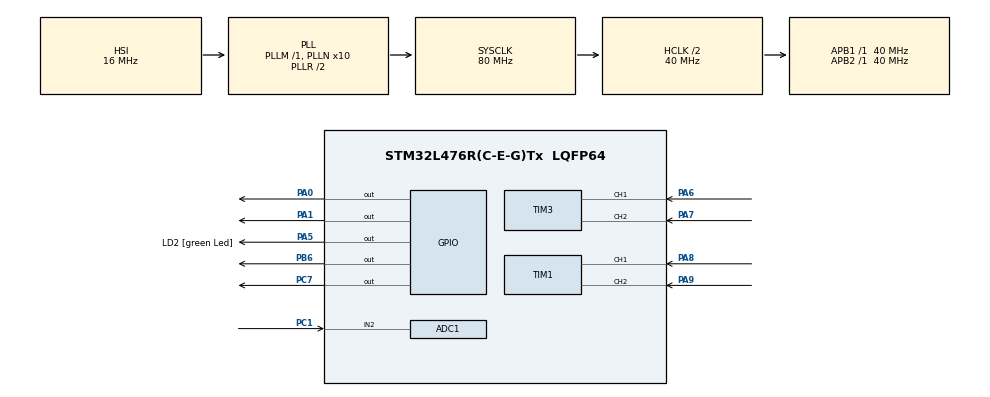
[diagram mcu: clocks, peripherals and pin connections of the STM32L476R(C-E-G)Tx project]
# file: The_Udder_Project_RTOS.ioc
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ADC1.Channel-0\#ChannelRegularConversion=ADC_CHANNEL_2
ADC1.ContinuousConvMode=ENABLE
ADC1.NbrOfConversionFlag=1
ADC1.OffsetNumber-0\#ChannelRegularConversion=ADC_OFFSET_NONE
ADC1.Rank-0\#ChannelRegularConversion=1
ADC1.SamplingTime-0\#ChannelRegularConversion=ADC_SAMPLETIME_2CYCLES_5
ADC1.master=1
Mcu.Family=STM32L4
Mcu.Name=STM32L476R(C-E-G)Tx
Mcu.Package=LQFP64
NVIC.PriorityGroup=NVIC_PRIORITYGROUP_4
PA0.GPIO_ModeDefaultOutputPP=GPIO_MODE_OUTPUT_PP
PA0.GPIO_PuPd=GPIO_PULLDOWN
PA0.GPIO_Speed=GPIO_SPEED_FREQ_LOW
PA0.PinState=GPIO_PIN_RESET
PA0.Signal=GPIO_Output
PA1.GPIO_PuPd=GPIO_PULLDOWN
PA1.Signal=GPIO_Output
PA13\ (JTMS-SWDIO).Mode=Trace_Asynchronous_SW
PA13\ (JTMS-SWDIO).Signal=SYS_JTMS-SWDIO
PA14\ (JTCK-SWCLK).Mode=Trace_Asynchronous_SW
PA14\ (JTCK-SWCLK).Signal=SYS_JTCK-SWCLK
PA5.GPIO_Label=LD2 [green Led]
PA5.GPIO_ModeDefaultOutputPP=GPIO_MODE_OUTPUT_PP
PA5.GPIO_PuPd=GPIO_NOPULL
PA5.GPIO_Speed=GPIO_SPEED_FREQ_LOW
PA5.Signal=GPIO_Output
PA6.Signal=S_TIM3_CH1
PA7.Signal=S_TIM3_CH2
PA8.Signal=S_TIM1_CH1
PA9.Signal=S_TIM1_CH2
PB3\ (JTDO-TRACESWO).Mode=Trace_Asynchronous_SW
PB3\ (JTDO-TRACESWO).Signal=SYS_JTDO-SWO
PB6.GPIO_PuPd=GPIO_PULLDOWN
PB6.Signal=GPIO_Output
PC1.Signal=ADCx_IN2
PC7.GPIO_PuPd=GPIO_PULLDOWN
PC7.Signal=GPIO_Output
PH0-OSC_IN\ (PH0).Mode=HSE-External-Oscillator
PH0-OSC_IN\ (PH0).Signal=RCC_OSC_IN
PH1-OSC_OUT\ (PH1).Mode=HSE-External-Oscillator
PH1-OSC_OUT\ (PH1).Signal=RCC_OSC_OUT
ProjectManager.HeapSize=0x200
ProjectManager.StackSize=0x400
ProjectManager.TargetToolchain=MDK-ARM V5.32
RCC.ADCFreq_Value=64000000
RCC.AHBCLKDivider=RCC_SYSCLK_DIV2
RCC.AHBFreq_Value=40000000
RCC.APB1Freq_Value=40000000
RCC.APB1TimFreq_Value=40000000
RCC.APB2Freq_Value=40000000
RCC.APB2TimFreq_Value=40000000
RCC.CortexFreq_Value=40000000
RCC.HCLKFreq_Value=40000000
RCC.HSE_VALUE=8000000
RCC.HSI_VALUE=16000000
RCC.LSE_VALUE=32768
RCC.MSI_VALUE=4000000
RCC.PLLN=10
RCC.PLLSourceVirtual=RCC_PLLSOURCE_HSI
RCC.PREFETCH_ENABLE=1
RCC.SYSCLKFreq_VALUE=80000000
RCC.SYSCLKSource=RCC_SYSCLKSOURCE_PLLCLK
RCC.USBFreq_Value=64000000
RCC.VCOOutputFreq_Value=160000000
SH.ADCx_IN2.0=ADC1_IN2,IN2-Single-Ended
SH.S_TIM1_CH1.0=TIM1_CH1,Encoder_Interface
SH.S_TIM1_CH2.0=TIM1_CH2,Encoder_Interface
SH.S_TIM3_CH1.0=TIM3_CH1,Encoder_Interface
SH.S_TIM3_CH2.0=TIM3_CH2,Encoder_Interface
TIM1.EncoderMode=TIM_ENCODERMODE_TI12
TIM3.EncoderMode=TIM_ENCODERMODE_TI12
board=NUCLEO-L476RG

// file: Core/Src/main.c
/* USER CODE BEGIN Header */
/**
  ******************************************************************************
  * @file           : main.c
  * @brief          : Main program body
  ******************************************************************************
  * @attention
  *
  * Copyright (c) 2023 STMicroelectronics.
  * All rights reserved.
  *
  * This software is licensed under terms that can be found in the LICENSE file
  * in the root directory of this software component.
  * If no LICENSE file comes with this software, it is provided AS-IS.
  *
  ******************************************************************************
  */
/* USER CODE END Header */
#include "main.h"
#include "adc.h"
#include "tim.h"
#include "gpio.h"

/* USER CODE BEGIN Includes */
#include <stdio.h>
#include "application.h"
#include "controller.h"
#include "peripherals.h"
/* USER CODE END Includes */

void SystemClock_Config(void);

/* USER CODE BEGIN 0 */
uint32_t Main_GetTickMillisec(void) {return HAL_GetTick();}
/* USER CODE END 0 */

int main(void)
{

  /* MCU Configuration--------------------------------------------------------*/

  /* Reset of all peripherals, Initializes the Flash interface and the Systick. */
  HAL_Init();

  /* Configure the system clock */
  SystemClock_Config();

  /* Initialize all configured peripherals */
  MX_GPIO_Init();
  MX_ADC1_Init();
  MX_TIM1_Init();
  MX_TIM3_Init();
  /* USER CODE BEGIN 2 */
	Application_Setup();
  /* USER CODE END 2 */

  /* Infinite loop */
  /* USER CODE BEGIN WHILE */
  while (1)
  {
		Application_Loop();
    /* USER CODE END WHILE */

  }
}

void SystemClock_Config(void)
{
  RCC_OscInitTypeDef RCC_OscInitStruct = {0};
  RCC_ClkInitTypeDef RCC_ClkInitStruct = {0};

  /** Configure the main internal regulator output voltage
  */
  if (HAL_PWREx_ControlVoltageScaling(PWR_REGULATOR_VOLTAGE_SCALE1) != HAL_OK)
  {
    Error_Handler();
  }

  /** Initializes the RCC Oscillators according to the specified parameters
  * in the RCC_OscInitTypeDef structure.
  */
  RCC_OscInitStruct.OscillatorType = RCC_OSCILLATORTYPE_HSI;
  RCC_OscInitStruct.HSIState = RCC_HSI_ON;
  RCC_OscInitStruct.HSICalibrationValue = RCC_HSICALIBRATION_DEFAULT;
  RCC_OscInitStruct.PLL.PLLState = RCC_PLL_ON;
  RCC_OscInitStruct.PLL.PLLSource = RCC_PLLSOURCE_HSI;
  RCC_OscInitStruct.PLL.PLLM = 1;
  RCC_OscInitStruct.PLL.PLLN = 10;
  RCC_OscInitStruct.PLL.PLLP = RCC_PLLP_DIV7;
  RCC_OscInitStruct.PLL.PLLQ = RCC_PLLQ_DIV2;
  RCC_OscInitStruct.PLL.PLLR = RCC_PLLR_DIV2;
  if (HAL_RCC_OscConfig(&RCC_OscInitStruct) != HAL_OK)
  {
    Error_Handler();
  }

  /** Initializes the CPU, AHB and APB buses clocks
  */
  RCC_ClkInitStruct.ClockType = RCC_CLOCKTYPE_HCLK|RCC_CLOCKTYPE_SYSCLK
                              |RCC_CLOCKTYPE_PCLK1|RCC_CLOCKTYPE_PCLK2;
  RCC_ClkInitStruct.SYSCLKSource = RCC_SYSCLKSOURCE_PLLCLK;
  RCC_ClkInitStruct.AHBCLKDivider = RCC_SYSCLK_DIV2;
  RCC_ClkInitStruct.APB1CLKDivider = RCC_HCLK_DIV1;
  RCC_ClkInitStruct.APB2CLKDivider = RCC_HCLK_DIV1;

  if (HAL_RCC_ClockConfig(&RCC_ClkInitStruct, FLASH_LATENCY_2) != HAL_OK)
  {
    Error_Handler();
  }
}

void Error_Handler(void)
{
  __disable_irq();
  while (1)
  {
  }
}
